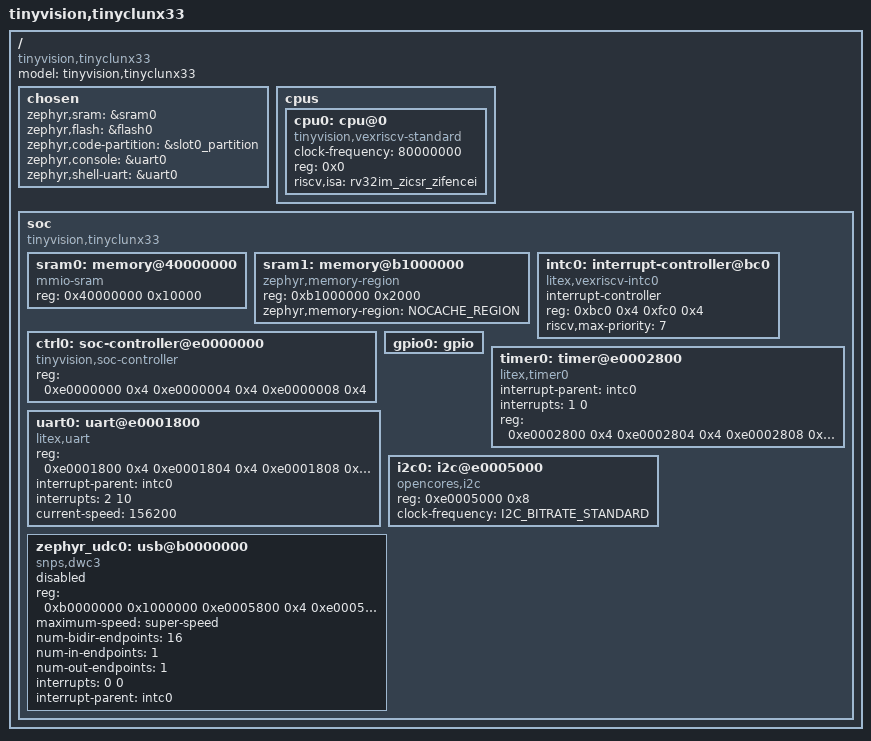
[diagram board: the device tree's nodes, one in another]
/*
 * Copyright (c) 2024-2025 tinyVision.ai Inc.
 *
 * SPDX-License-Identifier: Apache-2.0
 */

#include <zephyr/dt-bindings/i2c/i2c.h>

/ {
	compatible = "tinyvision,tinyclunx33";
	model = "tinyvision,tinyclunx33";
	#address-cells = <1>;
	#size-cells = <1>;

	chosen {
		zephyr,sram = &sram0;
		zephyr,flash = &flash0;
		zephyr,code-partition = &slot0_partition;
		zephyr,console = &uart0;
		zephyr,shell-uart = &uart0;
	};

	cpus {
		#address-cells = <1>;
		#size-cells = <0>;

		cpu0: cpu@0 {
			clock-frequency = <80000000>;
			compatible = "tinyvision,vexriscv-standard", "riscv";
			device_type = "cpu";
			reg = <0x0>;
			riscv,isa = "rv32im_zicsr_zifencei";
		};
	};

	soc {
		compatible = "tinyvision,tinyclunx33";
		ranges;
		#address-cells = <1>;
		#size-cells = <1>;


		/* Core SoC soft-peripherals */
		sram0: memory@40000000 {
			compatible = "mmio-sram";
			device_type = "memory";
			reg = <0x40000000 0x10000>;
		};

		sram1: memory@b1000000 {
			compatible = "zephyr,memory-region";
			device_type = "memory";
			reg = <0xb1000000 0x2000>;
			zephyr,memory-region = "NOCACHE_REGION";
		};

		ctrl0: soc-controller@e0000000 {
			compatible = "tinyvision,soc-controller";
			reg = <0xe0000000 0x4
				0xe0000004 0x4
				0xe0000008 0x4>;
			reg-names = "reset",
				"scratch",
				"bus_errors";
		};

		intc0: interrupt-controller@bc0 {
			compatible = "litex,vexriscv-intc0";
			interrupt-controller;
			reg = <0xbc0 0x4 0xfc0 0x4>;
			reg-names = "irq_mask", "irq_pending";
			riscv,max-priority = <7>;
			#address-cells = <0>;
			#interrupt-cells = <2>;
		};

		gpio0: gpio {
			/* No GPIO controller present yet */
		};

		timer0: timer@e0002800 {
			compatible = "litex,timer0";
			interrupt-parent = <&intc0>;
			interrupts = <1 0>;
			reg = <0xe0002800 0x4
				0xe0002804 0x4
				0xe0002808 0x4
				0xe000280c 0x4
				0xe0002810 0x4
				0xe0002814 0x4
				0xe0002818 0x4
				0xe000281c 0x4
				0xe0002820 0x4
				0xe0002824 0x8>;
			reg-names =
				"load",
				"reload",
				"en",
				"update_value",
				"value",
				"ev_status",
				"ev_pending",
				"ev_enable",
				"uptime_latch",
				"uptime_cycles";
		};

		uart0: uart@e0001800 {
			compatible = "litex,uart";
			reg = <0xe0001800 0x4
				0xe0001804 0x4
				0xe0001808 0x4
				0xe000180c 0x4
				0xe0001810 0x4
				0xe0001814 0x4
				0xe0001818 0x4
				0xe000181c 0x4>;
			reg-names = "rxtx",
				"txfull",
				"rxempty",
				"ev_status",
				"ev_pending",
				"ev_enable",
				"txempty",
				"rxfull";
			interrupt-parent = <&intc0>;
			interrupts = <2 10>;
			current-speed = <156200>;
		};

		i2c0: i2c@e0005000 {
			compatible = "opencores,i2c";
			reg = <0xe0005000 0x8>;
			clock-frequency = <I2C_BITRATE_STANDARD>;
			#address-cells = <1>;
			#size-cells = <0>;
		};

		zephyr_udc0: usb@b0000000 {
			compatible = "snps,dwc3";
			reg = <0xb0000000 0x1000000
				0xe0005800 0x4
				0xe0005804 0x4
				0xe0005808 0x4>;
			reg-names = "base",
				"ev_status",
				"ev_pending",
				"ev_enable";
			maximum-speed = "super-speed";
			num-bidir-endpoints = <16>;
			num-in-endpoints = <1>;
			num-out-endpoints = <1>;
			interrupts = <0 0>;
			interrupt-names = "usb";
			interrupt-parent = <&intc0>;

			status = "disabled";
		};
	};
};
